# PIC32MZ0512EFF144 device description
Architecture: 32xxxx; Family: PIC32MZEF; Series: PIC32MZ
Registers are 32-bit, read-write, no defined reset value unless marked. A register's access mark holds for its fields unless they carry their own. Offsets are from the block's base; [hi:lo] are bit positions; {n}, {i} and the like mark numbered series; 'fields as' and 'values as' point back to an identical list.

## CORE
Instances: CORE 0x0
0x00 zero ro
0x04 at
0x08 v0
0x0C v1
{0x10+4i} a{i} (i=0..3)
{0x20+4i} t{i} (i=0..7)
{0x40+4i} s{i} (i=0..7)
0x60 t8
0x64 t9
0x68 k0
0x6C k1
0x70 gp
0x74 sp
0x78 fp
0x7C ra
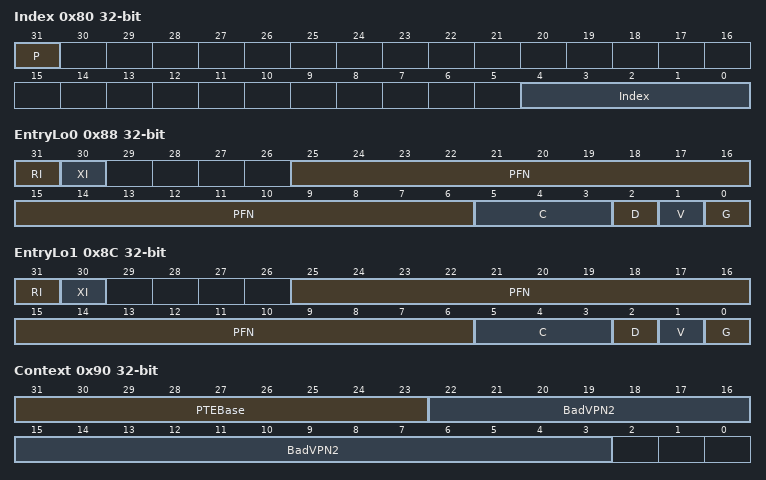
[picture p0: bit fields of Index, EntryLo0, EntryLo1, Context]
0x80 Index
  [31] P, [4:0] Index
0x84 Random
  [3:0] Random
0x88 EntryLo0
  [31] RI, [30] XI, [25:6] PFN, [5:3] C, [2] D, [1] V, [0] G
0x8C EntryLo1
  [31] RI, [30] XI, [25:6] PFN, [5:3] C, [2] D, [1] V, [0] G
0x90 Context
  [31:23] PTEBase, [22:3] BadVPN2
0x94 UserLocal
0x98 PageMask
  [28:13] Mask
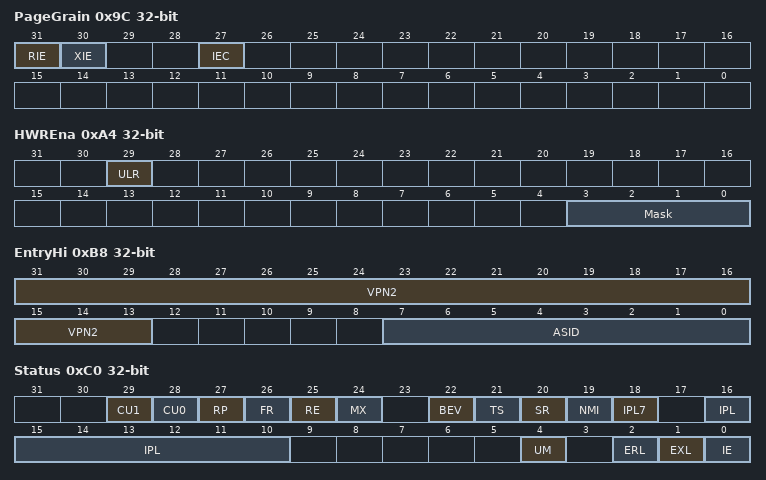
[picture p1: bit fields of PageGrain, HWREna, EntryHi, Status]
0x9C PageGrain
  [31] RIE, [30] XIE, [27] IEC
0xA0 Wired
  [4:0] Wired
0xA4 HWREna
  [29] ULR, [3:0] Mask
0xA8 BadVAddr ro
0xAC BadInstr ro
0xB0 BadInstrP ro
0xB4 Count
0xB8 EntryHi
  [31:13] VPN2, [7:0] ASID
0xBC Compare
0xC0 Status
  [29] CU1, [28] CU0, [27] RP, [26] FR, [25] RE, [24] MX, [22] BEV, [21] TS, [20] SR, [19] NMI, [18] IPL7, [16:10] IPL, [4] UM, [2] ERL, [1] EXL, [0] IE
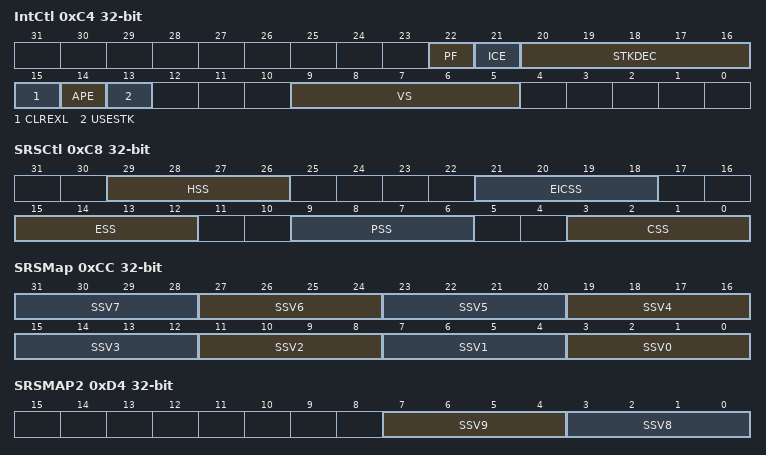
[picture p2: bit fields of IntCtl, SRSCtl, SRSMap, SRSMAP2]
0xC4 IntCtl
  [22] PF, [21] ICE, [20:16] STKDEC, [15] CLREXL, [14] APE, [13] USESTK, [9:5] VS
0xC8 SRSCtl
  [29:26] HSS, [21:18] EICSS, [15:12] ESS, [9:6] PSS, [3:0] CSS
0xCC SRSMap
  [4n+3:4n] SSV{n} (n=0..7)
0xD0 View_IPL
  [9:2] IPL
0xD4 SRSMAP2
  [7:4] SSV9, [3:0] SSV8
0xD8 GTOffset
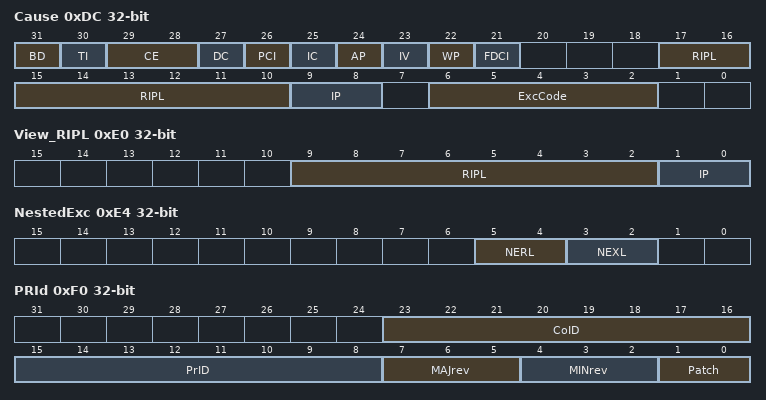
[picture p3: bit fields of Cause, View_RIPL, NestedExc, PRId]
0xDC Cause
  [31] BD, [30] TI, [29:28] CE, [27] DC, [26] PCI, [25] IC, [24] AP, [23] IV, [22] WP, [21] FDCI, [17:10] RIPL, [9:8] IP, [6:2] ExcCode
0xE0 View_RIPL
  [9:2] RIPL, [1:0] IP
0xE4 NestedExc
  [5:4] NERL, [3:2] NEXL
0xE8 EPC
0xEC NestedEPC
  [31:0] EPC
0xF0 PRId ro
  [23:16] CoID, [15:8] PrID, [7:5] MAJrev, [4:2] MINrev, [1:0] Patch
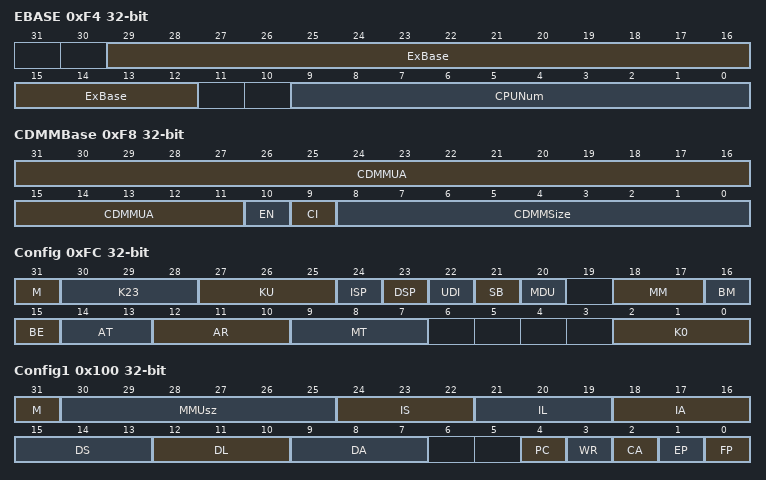
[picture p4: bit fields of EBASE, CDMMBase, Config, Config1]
0xF4 EBASE
  [29:12] ExBase, [9:0] CPUNum
0xF8 CDMMBase
  [31:11] CDMMUA, [10] EN, [9] CI, [8:0] CDMMSize
0xFC Config — Configuration Register; CP0 Register 16, Select 0
  [31] M
  [30:28] K23
  [27:25] KU
  [24] ISP — Instruction Scratch Pad RAM bit
    0=Instruction Scratch Pad RAM is not implemented
  [23] DSP — Data Scratch Pad RAM bit
    0=Data Scratch Pad RAM is not implemented
  [22] UDI — User-defined bit
    0=CorExtend User-Defined Instructions are not implemented
  [21] SB — SimpleBE bit
    1=Only Simple Byte Enables are allowed on the internal bus interface
  [20] MDU — Multiply/Divide Unit bit
    0=Fast, high-performance MDU
  [18:17] MM — Merge Mode bits
    2=Merging is allowed
  [16] BM — Burst Mode bit
    0=Burst order is sequential
  [15] BE — Endian Mode bit
    0=Little-endian
  [14:13] AT — Architecture Type bits
    0=MIPS32
  [12:10] AR — Architecture Revision Level bits
    1=MIPS32 Release 2
  [9:7] MT — MMU Type bits
    1=M-Class MPU Microprocessor core uses a TLB-based MMU
  [2:0] K0 — Kseg0 Coherency Algorithm bits
    3=Cacheable, non-coherent, write-back, write allocate; 2=Uncached; 1=Cacheable, non-coherent, write-through, write allocate; 0=Cacheable, non-coherent, write-through, no write allocate
0x100 Config1 ro — Configuration Register 1; CP0 Register 16, Select 1
  [31] M
  [30:25] MMUsz
  [24:22] IS — Instruction Cache Sets bits
    2=Contains 256 instruction cache sets per way
  [21:19] IL — Instruction-Cache Line bits
    3=Contains instruction cache line size of 16 bytes
  [18:16] IA — Instruction-Cache Associativity bits
    3=Contains 4-way instruction cache associativity
  [15:13] DS — Data-Cache Sets bits
    0=Contains 64 data cache sets per way
  [12:10] DL — Data-Cache Line bits
    3=Contains data cache line size of 16 bytes
  [9:7] DA — Data-Cache Associativity bits
    3=Contains the 4-way set associativity for the data cache
  [4] PC — Performance Counter bit
    1=The processor core contains Performance Counters
  [3] WR — Watch Register Presence bit
    1=No Watch registers are present
  [2] CA — Code Compression Implemented bit
    0=No MIPS16e present
  [1] EP — EJTAG Present bit
    1=Core implements EJTAG
  [0] FP — Floating Point Unit bit
    1=Floating Point Unit is present
0x104 Config2 ro
  [31] M
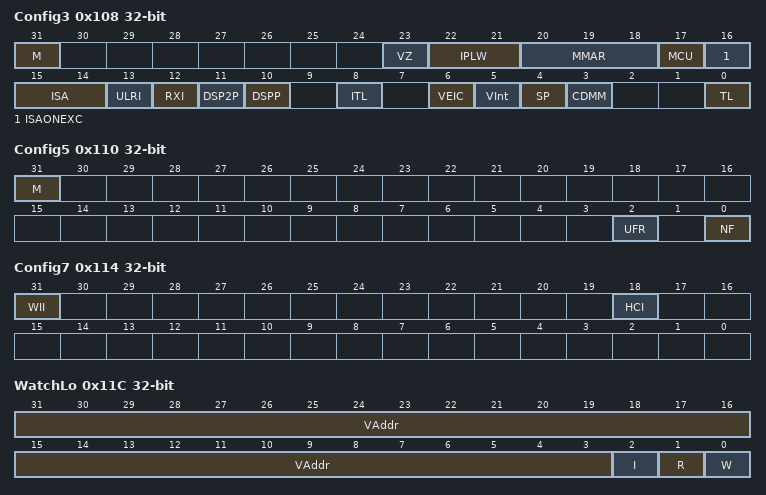
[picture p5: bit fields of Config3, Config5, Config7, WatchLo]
0x108 Config3 — Configuration Register 3; CP0 Register 16, Select 3
  [31] M
  [23] VZ
  [22:21] IPLW — Width of the Status IPL and Cause RIPL bits
    1=IPL and RIPL bits are 8-bits in width
  [20:18] MMAR — microMIPS Architecture Revision Level bits
    0=Release 1
  [17] MCU — MIPS MCU ASE Implemented bit
    1=MCU ASE is implemented
  [16] ISAONEXC — ISA on Exception bit
    1=microMIPS is used on entrance to an exception vector; 0=MIPS32 ISA is used on entrance to an exception vector
  [15:14] ISA — Instruction Set Availability bits
    3=Both MIPS32 and microMIPS are implemented; microMIPS is used when coming out of reset; 2=Both MIPS32 and microMIPS are implemented; MIPS32 ISA used when coming out of reset
  [13] ULRI — UserLocal Register Implemented bit
    1=UserLocal Coprocessor 0 register is implemented
  [12] RXI — RIE and XIE Implemented in PageGrain bit
    1=RIE and XIE bits are implemented
  [11] DSP2P — MIPS DSP ASE Revision 2 Presence bit
    1=DSP Revision 2 is present
  [10] DSPP — MIPS DSP ASE Presence bit
    1=DSP is present
  [8] ITL — Indicates that iFlowtrace hardware is present
    1=The iFlowtrace is implemented in the core
  [6] VEIC — External Vector Interrupt Controller bit
    1=Support for an external interrupt controller is implemented
  [5] VInt — Vector Interrupt bit
    1=Vector interrupts are implemented
  [4] SP — Small Page bit
    0=4 KB page size
  [3] CDMM — Common Device Memory Map bit
    1=CDMM is implemented
  [0] TL — Trace Logic bit
    0=Trace logic is not implemented
0x10C Config4 ro
  [31] M
0x110 Config5 — Configuration Register 5; CP0 Register 16, Select 5
  [31] M
  [2] UFR
  [0] NF — Nested Fault bit
    1=Nested Fault feature is implemented
0x114 Config7 ro — Configuration Register 7; CP0 Register 16, Select 7
  [31] WII — Wait IE Ignore bit
    1=Indicates that this processor will allow an interrupt to unblock a WAIT instruction
  [18] HCI
0x118 LLAddr ro
  [27:0] PAddr
0x11C WatchLo
  [31:3] VAddr, [2] I, [1] R, [0] W
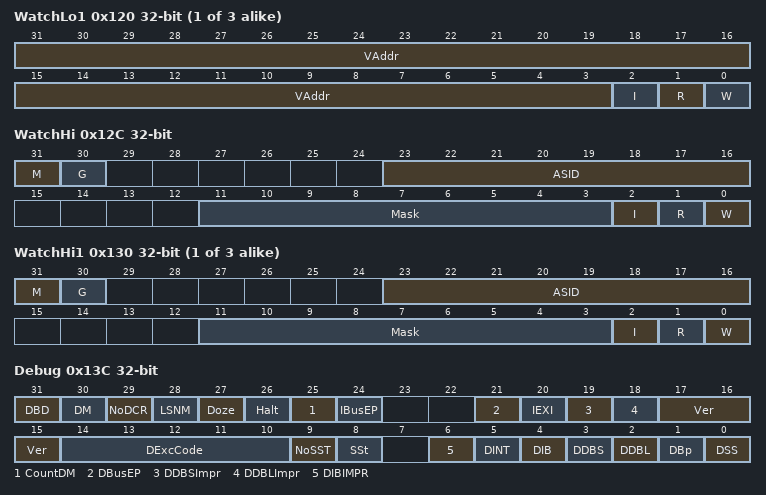
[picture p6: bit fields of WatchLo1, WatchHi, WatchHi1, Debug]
{0x11C+4i} WatchLo{i} (i=1..3)
  [31:3] VAddr, [2] I, [1] R, [0] W
0x12C WatchHi
  [31] M, [30] G, [23:16] ASID, [11:3] Mask, [2] I, [1] R, [0] W
{0x12C+4i} WatchHi{i} (i=1..3)
  [31] M, [30] G, [23:16] ASID, [11:3] Mask, [2] I, [1] R, [0] W
0x13C Debug
  [31] DBD, [30] DM, [29] NoDCR, [28] LSNM, [27] Doze, [26] Halt, [25] CountDM, [24] IBusEP, [21] DBusEP, [20] IEXI, [19] DDBSImpr, [18] DDBLImpr, [17:15] Ver, [14:10] DExcCode, [9] NoSST, [8] SSt, [6] DIBIMPR, [5] DINT, [4] DIB, [3] DDBS, [2] DDBL, [1] DBp, [0] DSS
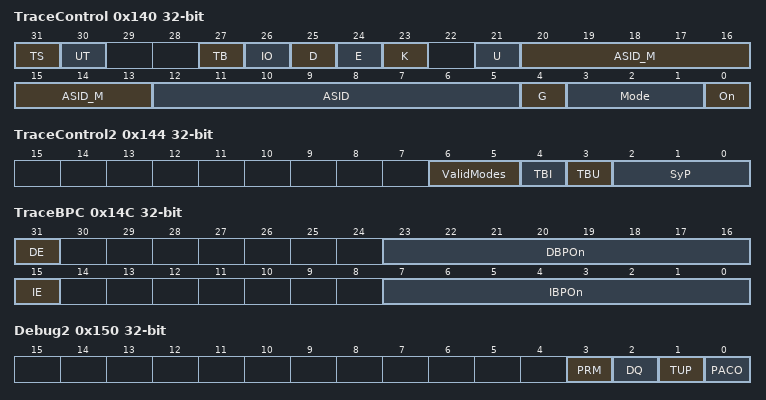
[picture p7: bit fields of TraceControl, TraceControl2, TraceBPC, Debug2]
0x140 TraceControl
  [31] TS, [30] UT, [27] TB, [26] IO, [25] D, [24] E, [23] K, [21] U, [20:13] ASID_M, [12:5] ASID, [4] G, [3:1] Mode, [0] On
0x144 TraceControl2 ro
  [6:5] ValidModes, [4] TBI, [3] TBU, [2:0] SyP
0x148 UserTraceData
  [31:0] Data
0x14C TraceBPC
  [31] DE, [23:16] DBPOn, [15] IE, [7:0] IBPOn
0x150 Debug2 ro
  [3] PRM, [2] DQ, [1] TUP, [0] PACO
0x154 DEPC
0x158 UserTraceData2
  [31:0] Data
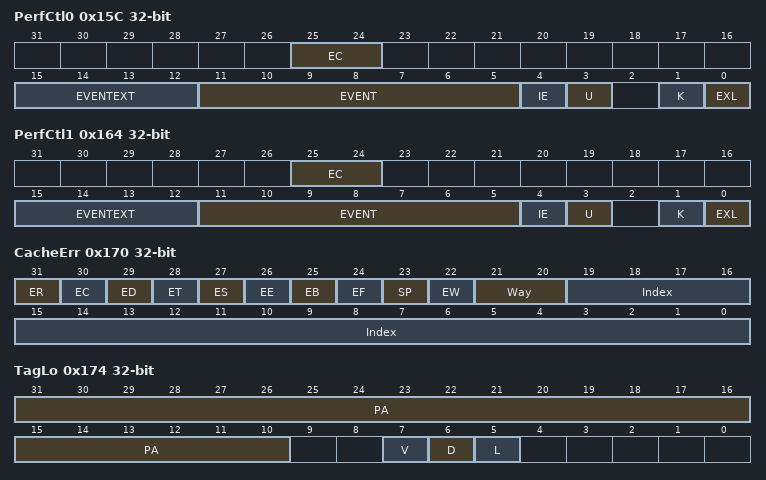
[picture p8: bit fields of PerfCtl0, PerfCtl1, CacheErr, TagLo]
0x15C PerfCtl0
  [25:24] EC, [15:12] EVENTEXT, [11:5] EVENT, [4] IE, [3] U, [1] K, [0] EXL
0x160 PerfCnt0
  [31:0] Counter
0x164 PerfCtl1
  fields as PerfCtl0
0x168 PerfCnt1
  [31:0] Counter
0x16C ErrCtl
  [29] WST
0x170 CacheErr ro
  [31] ER, [30] EC, [29] ED, [28] ET, [27] ES, [26] EE, [25] EB, [24] EF, [23] SP, [22] EW, [21:20] Way, [19:0] Index
0x174 TagLo
  [31:10] PA, [7] V, [6] D, [5] L
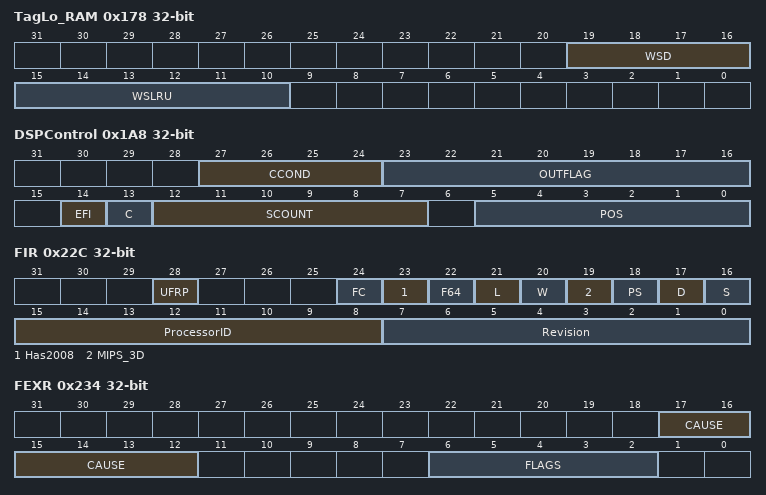
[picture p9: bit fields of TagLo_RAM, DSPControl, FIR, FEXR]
0x178 TagLo_RAM
  [19:16] WSD, [15:10] WSLRU
0x17C DataLo
  [31:0] DATA
0x180 ErrorEPC
0x184 DESAVE
0x188 lo
  [31:0] MDUlow
0x18C hi
  [31:0] MDUhigh
{0x188+8i} lo{i} (i=1..3)
  [31:0] MDUlow
{0x18C+8i} hi{i} (i=1..3)
  [31:0] MDUhigh
0x1A8 DSPControl
  [27:24] CCOND, [23:16] OUTFLAG, [14] EFI, [13] C, [12:7] SCOUNT, [5:0] POS
{0x1AC+4i} f{i} 64-bit (i=0..31)
0x22C FIR ro — Floating Point Implementation Register; CP1 Register 0
  [28] UFRP — User Mode FR Switching Instruction bit
    1=User mode FR switching instructions are supported; 0=User mode FR switching instructions are not supported
  [24] FC — Full Convert Ranges bit
    1=Full convert ranges are implemented (all numbers can be converted to another type by the FPU); 0=Full convert ranges are not implemented
  [23] Has2008 — IEEE-754-2008 bit
    1=MAC2008, ABS2008, NAN2008 bits exist within the FCSR register; 0=MAC2009, ABS2008, and NAN2008 bits do not exist within the FCSR register
  [22] F64 — 64-bit FPU bit
    1=This is a 64-bit FPU; 0=This is not a 64-bit FPU
  [21] L — Long Fixed Point Data Type bit
    1=Long fixed point data types are implemented; 0=Long fixed point data types are not implemented
  [20] W — Word Fixed Point data type bit
    1=Word fixed point data types are implemented; 0=Word fixed point data types are not implemented
  [19] MIPS_3D
  [18] PS — Paired Single Floating Point data bit
    1=PS floating point is implemented; 0=PS floating point is not implemented
  [17] D — Double-precision Floating Point Data bit
    1=Double-precision floating point data types are implemented; 0=Double-precision floating point data types are not implemented
  [16] S — Single-precision Floating Point Data bit
    1=Single-precision floating point data types are implemented; 0=Single-precision floating point data types are not implemented
  [15:8] ProcessorID
  [7:0] Revision
0x230 FCCR — Floating Point Condition Codes Register; CP1 Register 25
  [7:0] FCC
0x234 FEXR — Floating Point Exceptions Status Register; CP1 Register 26
  [17:12] CAUSE, [6:2] FLAGS
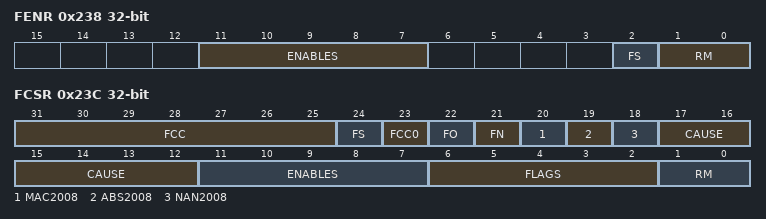
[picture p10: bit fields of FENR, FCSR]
0x238 FENR — Floating Point Exceptions and Modes Enable Register; CP1 Register 28
  [11:7] ENABLES
  [2] FS — Flush to Zero control bit
    1=Denormal input operands are flushed to zero. Tiny results are flushed to either zero or the applied format's smallest normalized number (MinNorm) depending on the rounding mode settings.; 0=Denormal input operands result in an Unimplemented Operation exception
  [1:0] RM — Rounding Mode control bits
    3=Round towards Minus Infinity (-?); 2=Round towards Plus Infinity (+?); 1=Round toward Zero (0); 0=Round to Nearest
0x23C FCSR — Floating Point Control and Status Register; CP1 Register 31
  [31:25] FCC
  [24] FS — Flush to Zero control bit
    values as FENR.FS
  [23] FCC0
  [22] FO — Flush Override Control bit
    1=The intermediate result is kept in an internal format, which can be perceived as having the usual mantissa precision but with unlimited exponent precision and without forcing to a specific value or taking an exception; 0=Handling of Tiny Result values depends on setting of the FS bit
  [21] FN — Flush to Nearest Control bit
    1=Final result is rounded to either zero or 2E_min (MinNorm), whichever is closest when in Round to Nearest (RN) rounding mode. For other rounding modes, a final result is given as if FS was set to 1.; 0=Handling of Tiny Result values depends on setting of the FS bit
  [20] MAC2008 — Fused Multiply Add mode control bit
    0=Unfused multiply-add. Intermediary multiplication results are rounded to the destination format.
  [19] ABS2008 — Absolute value format control bit
    1=ABS.fmt and NEG.fmt instructions compliant with IEEE Standard 754-2008. The ABS and NEG functions accept QNAN inputs without trapping.
  [18] NAN2008 — NaN Encoding control bit
    1=Quiet and signaling NaN encodings recommended by the IEEE Standard 754-2008. A quiet NaN is encoded with the first bit of the fraction being 1 and a signaling NaN is encoded with the first bit of the fraction being 0.
  [17:12] CAUSE
  [11:7] ENABLES
  [6:2] FLAGS
  [1:0] RM — Rounding Mode control bits
    values as FENR.RM
0x240 KScratch1
0x244 KScratch2
